AUTOSAR XML (schema 00049)
package /RB/PT/PCT_ASW1/SwComponentTypes
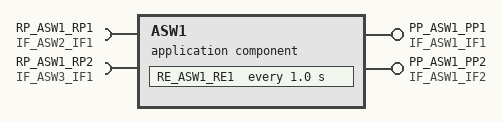
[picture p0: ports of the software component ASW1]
  application sw component type ASW1
    provide port PP_ASW1_PP1: provided-interface=IF_ASW1_IF1
    require port RP_ASW1_RP1: required-interface=IF_ASW2_IF1
    provide port PP_ASW1_PP2: provided-interface=IF_ASW1_IF2
    require port RP_ASW1_RP2: required-interface=IF_ASW3_IF1
    behavior IB_ASW1_IB1: data-type-mapping=[DTMS_ASW1_1, DTMS_ASW1_3, DTMS_ASW1_2]
      timing event TE_ASW1_TE1: start-on-event=RE_ASW1_RE1, period=1.0
      runnable RE_ASW1_RE1: symbol=ASW1_10ms
        data-receive-point-by-values:
          access DRP_ASW1_DRP1: accessed-variable=RP_ASW1_RP1.VDP_ASW2_Var1
          access DRP_ASW1_DRP2: accessed-variable=RP_ASW1_RP2.VDP_ASW3_Var1
        data-send-points:
          access DSP_ASW1_DSP1: accessed-variable=PP_ASW1_PP1.VDP_ASW1_Var1
          access DSP_ASW1_DSP2: accessed-variable=PP_ASW1_PP2.VDP_ASW1_Var2
package /RB/PT/PCT_ASW1/PortInterfaces
  4 x sender receiver interface:
    IF_ASW1_IF1
      data VDP_ASW1_Var1: type=ADT_ASW1_uint32
    IF_ASW2_IF1
      data VDP_ASW2_Var1: type=ADT_ASW2_uint32
    IF_ASW1_IF2
      data VDP_ASW1_Var2: type=ADT_ASW1_uint32
    IF_ASW3_IF1
      data VDP_ASW3_Var1: type=ADT_ASW3_uint32
package /RB/PT/PCT_ASW1/ApplicationDataTypes
  app type ADT_ASW1_uint32: category=VALUE, sw-calibration-access=READ-ONLY
package /RB/PT/PCT_ASW1/ImplementationDataTypes
  impl type IDT_ASW1_uint32: implementation-data-type=uint32
package /RB/PT/PCT_ASW1/DataTypeMappingSets
  data type mapping set DTMS_ASW1_{1..3}: data-type-map{application-data-type=ADT_ASW{1..3}_uint32, implementation-data-type=IDT_ASW{1..3}_uint32}
